# npck3m7k register map
Registers are 8-bit, read-write, no defined reset value unless marked. A register's access mark holds for its fields unless they carry their own. Offsets are from the block's base; [hi:lo] are bit positions; {n}, {i} and the like mark numbered series.

## LCT — LONG COUNTDOWN TIMER
Base 0x400DD000
0x00 LCTVER
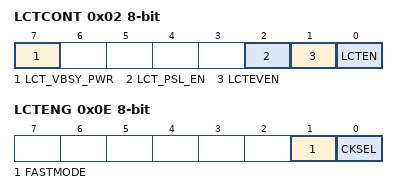
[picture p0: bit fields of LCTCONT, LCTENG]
0x02 LCTCONT
  [7] LCT_VBSY_PWR, [2] LCT_PSL_EN, [1] LCTEVEN, [0] LCTEN
0x04 LCTSTAT
  [0] LCTEVST
0x05 LCTSECOND
0x06 LCTMINUT
0x08 LCTHOUR
  [4:0] HOURS
0x0A LCTDAY
  [4:0] DAYS
0x0C LCTWEEK
  [3:0] WEEKS
0x0E LCTENG
  [1] FASTMODE, [0] CKSEL

## MTC — MONOTONIC COUNTER
Base 0x400B7000
0x00 TTC 32-bit
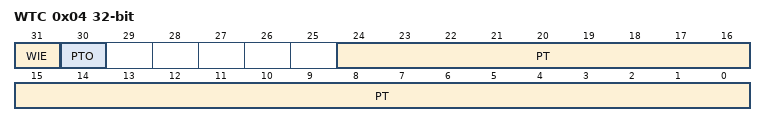
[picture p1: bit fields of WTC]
0x04 WTC 32-bit
  [31] WIE, [30] PTO, [24:0] PT
0x08 MTCTST
  [0] MTFEN

## TWD — TIMER AND WATCHDOG
Base 0x400D8000
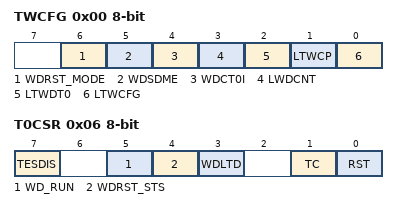
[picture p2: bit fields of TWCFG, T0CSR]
0x00 TWCFG
  [6] WDRST_MODE, [5] WDSDME, [4] WDCT0I, [3] LWDCNT, [2] LTWDT0, [1] LTWCP, [0] LTWCFG
0x02 TWCP
0x04 TWDT0 16-bit
0x06 T0CSR
  [7] TESDIS, [5] WD_RUN, [4] WDRST_STS, [3] WDLTD, [1] TC, [0] RST
0x08 WDCNT
0x0A WDSDM
0x0C TWMT0 16-bit
0x0E TWMWD
0x10 WDCP
0x14 TWD_VER

## ITIM32-1 — INTERNAL 32-BIT TIMER
Base 0x400B0000
Same registers: ITIM32-2 0x400B2000, ITIM32-3 0x400B4000, ITIM32-4 0x400B6000, ITIM32-5 0x400B8000, ITIM32-6 0x400BA000
0x00 ITCNT
0x01 ITPRE32n
0x02 ITCNT16 16-bit
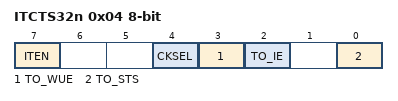
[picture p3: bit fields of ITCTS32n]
0x04 ITCTS32n
  [7] ITEN, [4] CKSEL, [3] TO_WUE, [2] TO_IE, [0] TO_STS
0x07 IT32VER
0x08 ITCNT32 32-bit

## ITIM64 — INTERNAL 64-BIT TIMER
Base 0x400BC000
0x01 ITPRE64
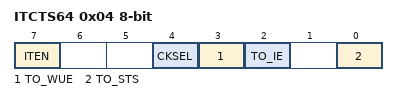
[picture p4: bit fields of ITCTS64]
0x04 ITCTS64
  [7] ITEN, [4] CKSEL, [3] TO_WUE, [2] TO_IE, [0] TO_STS
0x08 ITCNT64L 32-bit
0x0C ITCNT64H 32-bit

## MFT16-1 — MULTI-FUNCTION 16-BIT TIMER
Base 0x400E1000
Same registers: MFT16-2 0x400E3000, MFT16-3 0x400E5000, MFT16-4 0x400E7000, MFT16-5 0x400E9000
0x00 TnCNT1 16-bit
0x02 TnCRA 16-bit
0x04 TnCRB 16-bit
0x06 TnCNT2 16-bit
0x08 TnPRSC
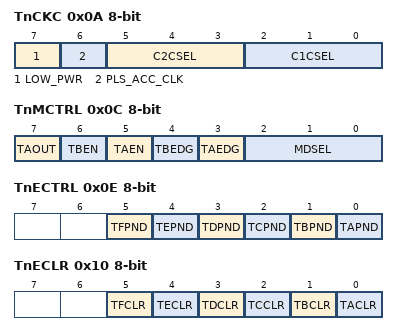
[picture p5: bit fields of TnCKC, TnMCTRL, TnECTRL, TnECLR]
0x0A TnCKC
  [7] LOW_PWR, [6] PLS_ACC_CLK, [5:3] C2CSEL, [2:0] C1CSEL
0x0C TnMCTRL
  [7] TAOUT, [6] TBEN, [5] TAEN, [4] TBEDG, [3] TAEDG, [2:0] MDSEL
0x0E TnECTRL
  [5] TFPND, [4] TEPND, [3] TDPND, [2] TCPND, [1] TBPND, [0] TAPND
0x10 TnECLR
  [5] TFCLR, [4] TECLR, [3] TDCLR, [2] TCCLR, [1] TBCLR, [0] TACLR
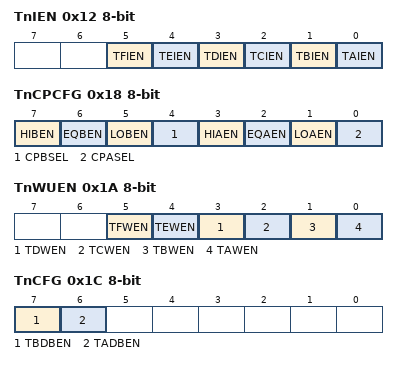
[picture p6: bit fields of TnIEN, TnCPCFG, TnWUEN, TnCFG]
0x12 TnIEN
  [5] TFIEN, [4] TEIEN, [3] TDIEN, [2] TCIEN, [1] TBIEN, [0] TAIEN
0x14 TnCPA 16-bit
0x16 TnCPB 16-bit
0x18 TnCPCFG
  [7] HIBEN, [6] EQBEN, [5] LOBEN, [4] CPBSEL, [3] HIAEN, [2] EQAEN, [1] LOAEN, [0] CPASEL
0x1A TnWUEN
  [5] TFWEN, [4] TEWEN, [3] TDWEN, [2] TCWEN, [1] TBWEN, [0] TAWEN
0x1C TnCFG
  [7] TBDBEN, [6] TADBEN
0x1E MFTnVER

## RTC
Base 0x400DD000
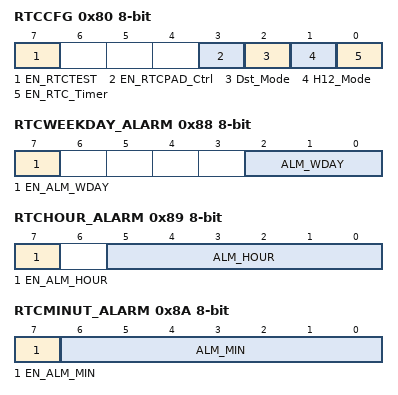
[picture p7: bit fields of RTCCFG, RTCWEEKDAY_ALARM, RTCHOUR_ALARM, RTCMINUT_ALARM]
0x80 RTCCFG
  [7] EN_RTCTEST, [3] EN_RTCPAD_Ctrl, [2] Dst_Mode, [1] H12_Mode, [0] EN_RTC_Timer
0x81 RTCSECOND
  [6:0] SECOND
0x82 RTCMINUT
  [6:0] MINUTE
0x83 RTCHOUR
  [5:0] HOUR
0x84 RTCDAY
  [5:0] DAY
0x85 RTCWEEKDAY
  [2:0] WEEKDAY
0x86 RTCMONTH
  [4:0] MONTH
0x87 RTCYEAR
  [7:0] YEAR
0x88 RTCWEEKDAY_ALARM
  [7] EN_ALM_WDAY, [2:0] ALM_WDAY
0x89 RTCHOUR_ALARM
  [7] EN_ALM_HOUR, [5:0] ALM_HOUR
0x8A RTCMINUT_ALARM
  [7] EN_ALM_MIN, [6:0] ALM_MIN
0x8B RTCINT_EN
  [0] EN_INT
0x8C RTCINT_FLG
  [0] ALMINT_FLAG
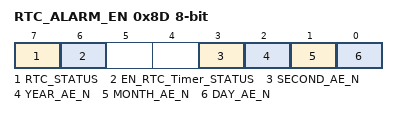
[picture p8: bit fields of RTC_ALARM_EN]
0x8D RTC_ALARM_EN
  [7] RTC_STATUS, [6] EN_RTC_Timer_STATUS, [3] SECOND_AE_N, [2] YEAR_AE_N, [1] MONTH_AE_N, [0] DAY_AE_N
0x8E RTCYEAR_ALARM
0x8F RTCMONTH_ALARM
  [4:0] ALM_MONTH
0x90 RTCDAY_ALARM
  [5:0] ALM_DAY
0x91 RTCSECOND_ALARM
  [6:0] ALM_SEC

## OWI — OWI Module
Base 0x400EB000
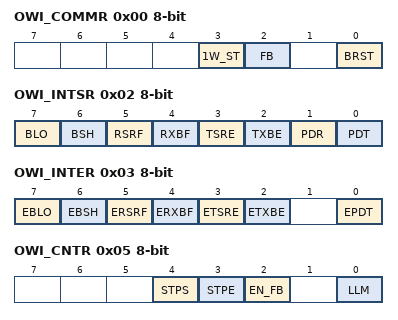
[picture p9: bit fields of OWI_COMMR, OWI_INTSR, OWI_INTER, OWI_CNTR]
0x00 OWI_COMMR
  [3] 1W_ST, [2] FB, [0] BRST
0x01 OWI_RXB
0x01 OWI_TXB
0x02 OWI_INTSR
  [7] BLO, [6] BSH, [5] RSRF, [4] RXBF, [3] TSRE, [2] TXBE, [1] PDR, [0] PDT
0x03 OWI_INTER
  [7] EBLO, [6] EBSH, [5] ERSRF, [4] ERXBF, [3] ETSRE, [2] ETXBE, [0] EPDT
0x04 OWI_CKDVR
0x05 OWI_CNTR
  [4] STPS, [3] STPE, [2] EN_FB, [0] LLM
0x07 OWI_VER

## ADC — ADC Module
Base 0x400D1000
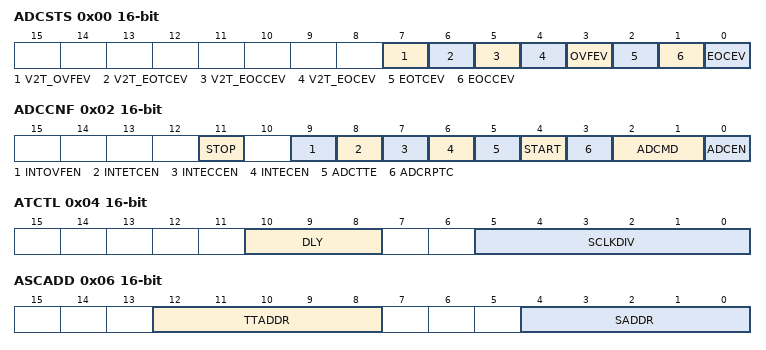
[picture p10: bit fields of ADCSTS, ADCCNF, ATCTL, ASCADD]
0x00 ADCSTS 16-bit
  [7] V2T_OVFEV, [6] V2T_EOTCEV, [5] V2T_EOCCEV, [4] V2T_EOCEV, [3] OVFEV, [2] EOTCEV, [1] EOCCEV, [0] EOCEV
0x02 ADCCNF 16-bit
  [11] STOP, [9] INTOVFEN, [8] INTETCEN, [7] INTECCEN, [6] INTECEN, [5] ADCTTE, [4] START, [3] ADCRPTC, [2:1] ADCMD, [0] ADCEN
0x04 ATCTL 16-bit
  [10:8] DLY, [5:0] SCLKDIV
0x06 ASCADD 16-bit
  [12:8] TTADDR, [4:0] SADDR
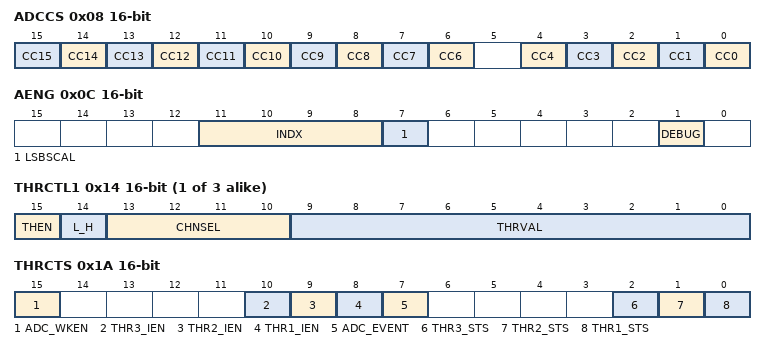
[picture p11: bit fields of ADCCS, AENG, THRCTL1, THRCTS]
0x08 ADCCS 16-bit
  [n] CC{n} (n=6..15), [n] CC{n} (n=0..4)
0x0C AENG 16-bit
  [11:8] INDX, [7] LSBSCAL, [1] DEBUG
0x12 AENG_DATA 16-bit
{0x12+2i} THRCTL{i} 16-bit (i=1..3)
  [15] THEN, [14] L_H, [13:10] CHNSEL, [9:0] THRVAL
0x1A THRCTS 16-bit
  [15] ADC_WKEN, [10] THR3_IEN, [9] THR2_IEN, [8] THR1_IEN, [7] ADC_EVENT, [2] THR3_STS, [1] THR2_STS, [0] THR1_STS
0x1E ADC_VER
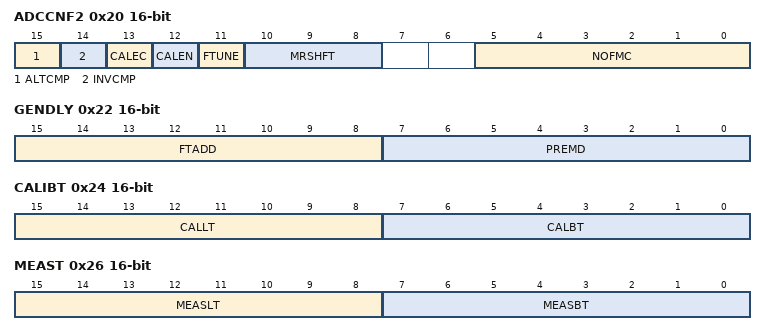
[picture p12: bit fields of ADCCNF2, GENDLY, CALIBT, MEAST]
0x20 ADCCNF2 16-bit
  [15] ALTCMP, [14] INVCMP, [13] CALEC, [12] CALEN, [11] FTUNE, [10:8] MRSHFT, [5:0] NOFMC
0x22 GENDLY 16-bit
  [15:8] FTADD, [7:0] PREMD
0x24 CALIBT 16-bit
  [15:8] CALLT, [7:0] CALBT
0x26 MEAST 16-bit
  [15:8] MEASLT, [7:0] MEASBT
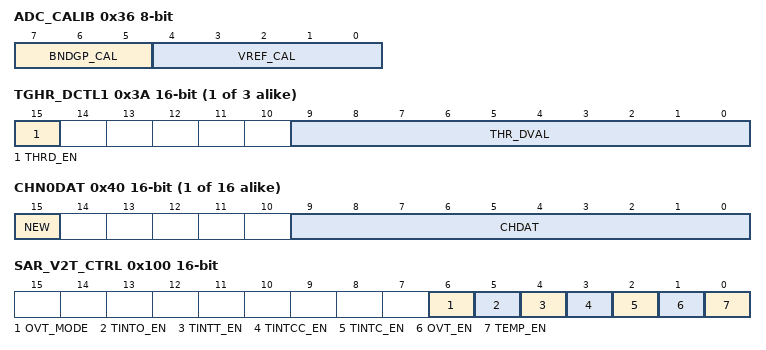
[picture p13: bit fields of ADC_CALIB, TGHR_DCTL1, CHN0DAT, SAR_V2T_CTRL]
0x36 ADC_CALIB
  [7:5] BNDGP_CAL, [4:0] VREF_CAL
0x38 ADC_MISC_CFG
  [1:0] RC_SEL
{0x38+2i} TGHR_DCTL{i} 16-bit (i=1..3)
  [15] THRD_EN, [9:0] THR_DVAL
{0x40+2i} CHN{i}DAT 16-bit (i=0..15)
  [15] NEW, [9:0] CHDAT
0x100 SAR_V2T_CTRL 16-bit
  [6] OVT_MODE, [5] TINTO_EN, [4] TINTT_EN, [3] TINTCC_EN, [2] TINTC_EN, [1] OVT_EN, [0] TEMP_EN
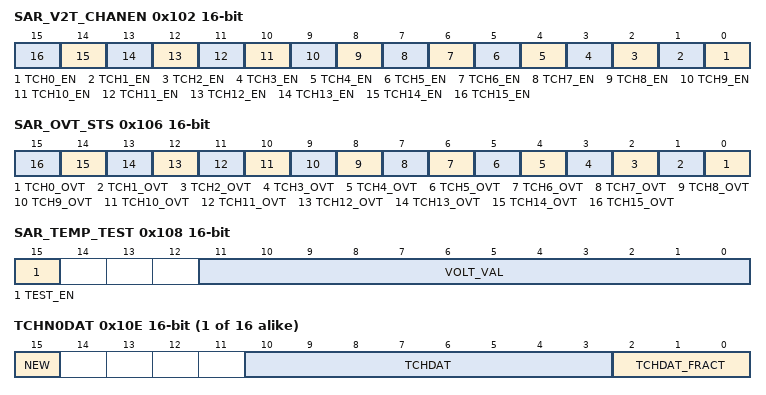
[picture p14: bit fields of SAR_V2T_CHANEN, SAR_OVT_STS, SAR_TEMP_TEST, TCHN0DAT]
0x102 SAR_V2T_CHANEN 16-bit
  [n] TCH{n}_EN (n=0..15)
0x106 SAR_OVT_STS 16-bit
  [n] TCH{n}_OVT (n=0..15)
0x108 SAR_TEMP_TEST 16-bit
  [15] TEST_EN, [11:0] VOLT_VAL
{0x10E+2i} TCHN{i}DAT 16-bit (i=0..15)
  [15] NEW, [10:3] TCHDAT, [2:0] TCHDAT_FRACT
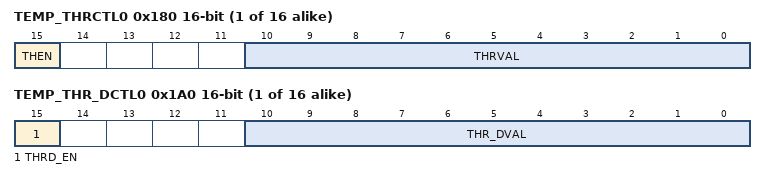
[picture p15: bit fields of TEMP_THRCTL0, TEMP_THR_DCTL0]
{0x180+2i} TEMP_THRCTL{i} 16-bit (i=0..15)
  [15] THEN, [10:0] THRVAL
{0x1A0+2i} TEMP_THR_DCTL{i} 16-bit (i=0..15)
  [15] THRD_EN, [10:0] THR_DVAL
